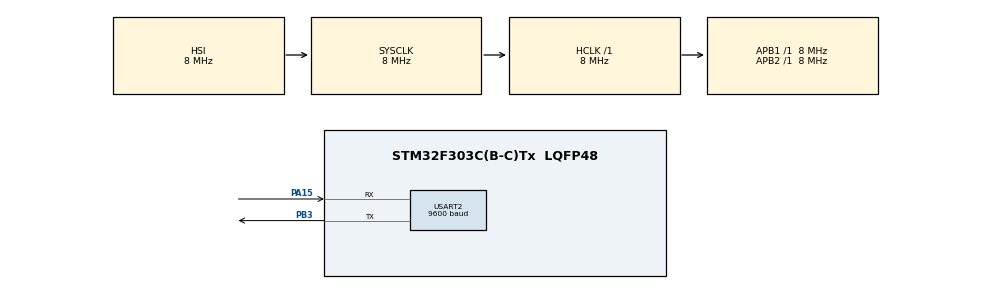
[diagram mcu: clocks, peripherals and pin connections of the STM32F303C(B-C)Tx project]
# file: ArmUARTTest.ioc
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Mcu.Family=STM32F3
Mcu.Name=STM32F303C(B-C)Tx
Mcu.Package=LQFP48
NVIC.PriorityGroup=NVIC_PRIORITYGROUP_4
NVIC.TIM2_IRQn=true\:0\:0\:false\:false\:true\:true
PA13.Mode=Serial_Wire
PA13.Signal=SYS_JTMS-SWDIO
PA14.Mode=Serial_Wire
PA14.Signal=SYS_JTCK-SWCLK
PA15.Mode=Asynchronous
PA15.Signal=USART2_RX
PB3.Mode=Asynchronous
PB3.Signal=USART2_TX
ProjectManager.HeapSize=0x200
ProjectManager.StackSize=0x400
ProjectManager.TargetToolchain=MDK-ARM V5
RCC.AHBFreq_Value=8000000
RCC.APB1Freq_Value=8000000
RCC.APB2Freq_Value=8000000
RCC.CortexFreq_Value=8000000
RCC.HSE_VALUE=8000000
RCC.HSI_VALUE=8000000
RCC.LSE_VALUE=32768
RCC.PLLMUL=RCC_PLL_MUL4
RCC.SYSCLKFreq_VALUE=8000000
RCC.USBFreq_Value=16000000
TIM2.Period=100
TIM2.Prescaler=16000
USART2.BaudRate=9600
USART2.VirtualMode-Asynchronous=VM_ASYNC
VP_TIM2_VS_ClockSourceINT.Mode=Internal
board=ArmUARTTest

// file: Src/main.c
/**
  ******************************************************************************
  * @file           : main.c
  * @brief          : Main program body
  ******************************************************************************
  ** This notice applies to any and all portions of this file
  * that are not between comment pairs USER CODE BEGIN and
  * USER CODE END. Other portions of this file, whether
  * inserted by the user or by software development tools
  * are owned by their respective copyright owners.
  *
  * COPYRIGHT(c) 2018 STMicroelectronics
  *
  * Redistribution and use in source and binary forms, with or without modification,
  * are permitted provided that the following conditions are met:
  *   1. Redistributions of source code must retain the above copyright notice,
  *      this list of conditions and the following disclaimer.
  *   2. Redistributions in binary form must reproduce the above copyright notice,
  *      this list of conditions and the following disclaimer in the documentation
  *      and/or other materials provided with the distribution.
  *   3. Neither the name of STMicroelectronics nor the names of its contributors
  *      may be used to endorse or promote products derived from this software
  *      without specific prior written permission.
  *
  * THIS SOFTWARE IS PROVIDED BY THE COPYRIGHT HOLDERS AND CONTRIBUTORS "AS IS"
  * AND ANY EXPRESS OR IMPLIED WARRANTIES, INCLUDING, BUT NOT LIMITED TO, THE
  * IMPLIED WARRANTIES OF MERCHANTABILITY AND FITNESS FOR A PARTICULAR PURPOSE ARE
  * DISCLAIMED. IN NO EVENT SHALL THE COPYRIGHT HOLDER OR CONTRIBUTORS BE LIABLE
  * FOR ANY DIRECT, INDIRECT, INCIDENTAL, SPECIAL, EXEMPLARY, OR CONSEQUENTIAL
  * DAMAGES (INCLUDING, BUT NOT LIMITED TO, PROCUREMENT OF SUBSTITUTE GOODS OR
  * SERVICES; LOSS OF USE, DATA, OR PROFITS; OR BUSINESS INTERRUPTION) HOWEVER
  * CAUSED AND ON ANY THEORY OF LIABILITY, WHETHER IN CONTRACT, STRICT LIABILITY,
  * OR TORT (INCLUDING NEGLIGENCE OR OTHERWISE) ARISING IN ANY WAY OUT OF THE USE
  * OF THIS SOFTWARE, EVEN IF ADVISED OF THE POSSIBILITY OF SUCH DAMAGE.
  *
  ******************************************************************************
  */
#include "main.h"
#include "stm32f3xx_hal.h"

TIM_HandleTypeDef htim2;

UART_HandleTypeDef huart2;

/* USER CODE BEGIN PV */
/* Private variables ---------------------------------------------------------*/

/* USER CODE END PV */

void SystemClock_Config(void);
static void MX_GPIO_Init(void);
static void MX_TIM2_Init(void);
static void MX_USART2_UART_Init(void);

/* USER CODE BEGIN PFP */
/* Private function prototypes -----------------------------------------------*/

/* USER CODE END PFP */

/* USER CODE BEGIN 0 */
#include "stdio.h"
#include "string.h"
char aTxBuffer[1024];

/* USER CODE END 0 */

int main(void)
{

  /* MCU Configuration----------------------------------------------------------*/

  /* Reset of all peripherals, Initializes the Flash interface and the Systick. */
  HAL_Init();

  /* Configure the system clock */
  SystemClock_Config();

  /* Initialize all configured peripherals */
  MX_GPIO_Init();
  MX_TIM2_Init();
  MX_USART2_UART_Init();
  /* USER CODE BEGIN 2 */
	HAL_TIM_Base_Start_IT(&htim2);
  /* USER CODE END 2 */

  /* Infinite loop */
  while (1)
  {

  }

}

void SystemClock_Config(void)
{

  RCC_OscInitTypeDef RCC_OscInitStruct;
  RCC_ClkInitTypeDef RCC_ClkInitStruct;
  RCC_PeriphCLKInitTypeDef PeriphClkInit;

    /**Initializes the CPU, AHB and APB busses clocks
    */
  RCC_OscInitStruct.OscillatorType = RCC_OSCILLATORTYPE_HSI;
  RCC_OscInitStruct.HSIState = RCC_HSI_ON;
  RCC_OscInitStruct.HSICalibrationValue = 16;
  RCC_OscInitStruct.PLL.PLLState = RCC_PLL_NONE;
  if (HAL_RCC_OscConfig(&RCC_OscInitStruct) != HAL_OK)
  {
    _Error_Handler(__FILE__, __LINE__);
  }

    /**Initializes the CPU, AHB and APB busses clocks
    */
  RCC_ClkInitStruct.ClockType = RCC_CLOCKTYPE_HCLK|RCC_CLOCKTYPE_SYSCLK
                              |RCC_CLOCKTYPE_PCLK1|RCC_CLOCKTYPE_PCLK2;
  RCC_ClkInitStruct.SYSCLKSource = RCC_SYSCLKSOURCE_HSI;
  RCC_ClkInitStruct.AHBCLKDivider = RCC_SYSCLK_DIV1;
  RCC_ClkInitStruct.APB1CLKDivider = RCC_HCLK_DIV1;
  RCC_ClkInitStruct.APB2CLKDivider = RCC_HCLK_DIV1;

  if (HAL_RCC_ClockConfig(&RCC_ClkInitStruct, FLASH_LATENCY_0) != HAL_OK)
  {
    _Error_Handler(__FILE__, __LINE__);
  }

  PeriphClkInit.PeriphClockSelection = RCC_PERIPHCLK_USART2;
  PeriphClkInit.Usart2ClockSelection = RCC_USART2CLKSOURCE_PCLK1;
  if (HAL_RCCEx_PeriphCLKConfig(&PeriphClkInit) != HAL_OK)
  {
    _Error_Handler(__FILE__, __LINE__);
  }

    /**Configure the Systick interrupt time
    */
  HAL_SYSTICK_Config(HAL_RCC_GetHCLKFreq()/1000);

    /**Configure the Systick
    */
  HAL_SYSTICK_CLKSourceConfig(SYSTICK_CLKSOURCE_HCLK);

  /* SysTick_IRQn interrupt configuration */
  HAL_NVIC_SetPriority(SysTick_IRQn, 0, 0);
}

/* TIM2 init function */
static void MX_TIM2_Init(void)
{

  TIM_ClockConfigTypeDef sClockSourceConfig;
  TIM_MasterConfigTypeDef sMasterConfig;

  htim2.Instance = TIM2;
  htim2.Init.Prescaler = 16000;
  htim2.Init.CounterMode = TIM_COUNTERMODE_UP;
  htim2.Init.Period = 100;
  htim2.Init.ClockDivision = TIM_CLOCKDIVISION_DIV1;
  htim2.Init.AutoReloadPreload = TIM_AUTORELOAD_PRELOAD_DISABLE;
  if (HAL_TIM_Base_Init(&htim2) != HAL_OK)
  {
    _Error_Handler(__FILE__, __LINE__);
  }

  sClockSourceConfig.ClockSource = TIM_CLOCKSOURCE_INTERNAL;
  if (HAL_TIM_ConfigClockSource(&htim2, &sClockSourceConfig) != HAL_OK)
  {
    _Error_Handler(__FILE__, __LINE__);
  }

  sMasterConfig.MasterOutputTrigger = TIM_TRGO_RESET;
  sMasterConfig.MasterSlaveMode = TIM_MASTERSLAVEMODE_DISABLE;
  if (HAL_TIMEx_MasterConfigSynchronization(&htim2, &sMasterConfig) != HAL_OK)
  {
    _Error_Handler(__FILE__, __LINE__);
  }

}

/* USART2 init function */
static void MX_USART2_UART_Init(void)
{

  huart2.Instance = USART2;
  huart2.Init.BaudRate = 9600;
  huart2.Init.WordLength = UART_WORDLENGTH_8B;
  huart2.Init.StopBits = UART_STOPBITS_1;
  huart2.Init.Parity = UART_PARITY_NONE;
  huart2.Init.Mode = UART_MODE_TX_RX;
  huart2.Init.HwFlowCtl = UART_HWCONTROL_NONE;
  huart2.Init.OverSampling = UART_OVERSAMPLING_16;
  huart2.Init.OneBitSampling = UART_ONE_BIT_SAMPLE_DISABLE;
  huart2.AdvancedInit.AdvFeatureInit = UART_ADVFEATURE_NO_INIT;
  if (HAL_UART_Init(&huart2) != HAL_OK)
  {
    _Error_Handler(__FILE__, __LINE__);
  }

}

/** Configure pins as
        * Analog
        * Input
        * Output
        * EVENT_OUT
        * EXTI
        * Free pins are configured automatically as Analog (this feature is enabled through
        * the Code Generation settings)
*/
static void MX_GPIO_Init(void)
{

  GPIO_InitTypeDef GPIO_InitStruct;

  /* GPIO Ports Clock Enable */
  __HAL_RCC_GPIOC_CLK_ENABLE();
  __HAL_RCC_GPIOF_CLK_ENABLE();
  __HAL_RCC_GPIOA_CLK_ENABLE();
  __HAL_RCC_GPIOB_CLK_ENABLE();

  /*Configure GPIO pins : PC13 PC14 PC15 */
  GPIO_InitStruct.Pin = GPIO_PIN_13|GPIO_PIN_14|GPIO_PIN_15;
  GPIO_InitStruct.Mode = GPIO_MODE_ANALOG;
  GPIO_InitStruct.Pull = GPIO_NOPULL;
  HAL_GPIO_Init(GPIOC, &GPIO_InitStruct);

  /*Configure GPIO pins : PF0 PF1 */
  GPIO_InitStruct.Pin = GPIO_PIN_0|GPIO_PIN_1;
  GPIO_InitStruct.Mode = GPIO_MODE_ANALOG;
  GPIO_InitStruct.Pull = GPIO_NOPULL;
  HAL_GPIO_Init(GPIOF, &GPIO_InitStruct);

  /*Configure GPIO pins : PA0 PA1 PA2 PA3
                           PA4 PA5 PA6 PA7
                           PA8 PA9 PA10 PA11
                           PA12 */
  GPIO_InitStruct.Pin = GPIO_PIN_0|GPIO_PIN_1|GPIO_PIN_2|GPIO_PIN_3
                          |GPIO_PIN_4|GPIO_PIN_5|GPIO_PIN_6|GPIO_PIN_7
                          |GPIO_PIN_8|GPIO_PIN_9|GPIO_PIN_10|GPIO_PIN_11
                          |GPIO_PIN_12;
  GPIO_InitStruct.Mode = GPIO_MODE_ANALOG;
  GPIO_InitStruct.Pull = GPIO_NOPULL;
  HAL_GPIO_Init(GPIOA, &GPIO_InitStruct);

  /*Configure GPIO pins : PB0 PB1 PB2 PB10
                           PB11 PB12 PB13 PB14
                           PB15 PB4 PB5 PB6
                           PB7 PB8 PB9 */
  GPIO_InitStruct.Pin = GPIO_PIN_0|GPIO_PIN_1|GPIO_PIN_2|GPIO_PIN_10
                          |GPIO_PIN_11|GPIO_PIN_12|GPIO_PIN_13|GPIO_PIN_14
                          |GPIO_PIN_15|GPIO_PIN_4|GPIO_PIN_5|GPIO_PIN_6
                          |GPIO_PIN_7|GPIO_PIN_8|GPIO_PIN_9;
  GPIO_InitStruct.Mode = GPIO_MODE_ANALOG;
  GPIO_InitStruct.Pull = GPIO_NOPULL;
  HAL_GPIO_Init(GPIOB, &GPIO_InitStruct);

}

/* USER CODE BEGIN 4 */
int nbtime=1;
void HAL_TIM_PeriodElapsedCallback(TIM_HandleTypeDef *htim){
	sprintf(aTxBuffer, "Testing Uart %d times\r\n", ++nbtime);
	HAL_UART_Transmit(&huart2, (uint8_t *)aTxBuffer, strlen(aTxBuffer), 5000);
}
/* USER CODE END 4 */

void _Error_Handler(char *file, int line)
{
  while(1)
  {
  }
}

/************************ (C) COPYRIGHT STMicroelectronics *****END OF FILE****/
